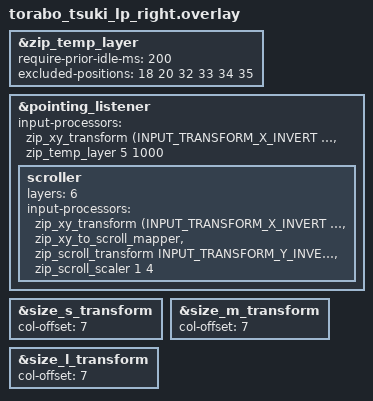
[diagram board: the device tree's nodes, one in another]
#define TORABO_TSUKI_LP_RIGHT 1
#define TORABO_TSUKI_LP_MATRIX_COL_OFFSET 7

#include "torabo_tsuki_lp.dtsi"
#include <input/processors.dtsi>
#include <dt-bindings/zmk/input_transform.h>

// オートマウスレーヤーのオプション
&zip_temp_layer {
    require-prior-idle-ms = <200>;            // キー入力後、自動切替を抑止する時間
    excluded-positions = <18 20 32 33 34 35>; // AMLを解除しない物理キーの位置番号、これ以外のキーを押すと解除
};

&pointing_listener {
    input-processors = 
        <&zip_xy_transform (INPUT_TRANSFORM_X_INVERT | INPUT_TRANSFORM_Y_INVERT)>,
        <&zip_temp_layer 5 1000>; // オートマウスレイヤー、対象マウスレイヤー、解除時間(ms)

    scroller {
    layers = <6>;
    input-processors =
        <&zip_xy_transform (INPUT_TRANSFORM_X_INVERT | INPUT_TRANSFORM_Y_INVERT)>,
        <&zip_xy_to_scroll_mapper>,
        <&zip_scroll_transform INPUT_TRANSFORM_Y_INVERT>,
        <&zip_scroll_scaler 1 4>;
    };
};

&size_s_transform {
    col-offset = <7>;
};

&size_m_transform {
    col-offset = <7>;
};

&size_l_transform {
    col-offset = <7>;
};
